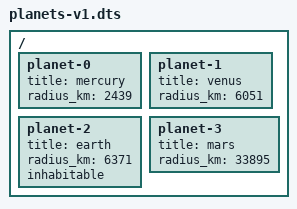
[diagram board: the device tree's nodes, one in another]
/dts-v1/;

/ {
	planet-0 {
		title = "mercury";
		radius_km = <2439>;
	};

	planet-1 {
		title = "venus";
		radius_km = <6051>;
	};

	planet-2 {
		title = "earth";
		radius_km = <6371>;
		inhabitable;
	};

	planet-3 {
		title = "mars";
		radius_km = <33895>;
	};

};
